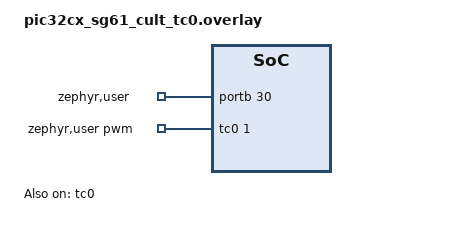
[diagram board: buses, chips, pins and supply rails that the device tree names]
/*
 * Copyright (c) 2026 Microchip Technology Inc.
 *
 * SPDX-License-Identifier: Apache-2.0
 */

/* connect the PB31 to PB30 */

#include <zephyr/dt-bindings/gpio/gpio.h>

/ {
	zephyr,user {
		pwms = <&tc0 1 PWM_MSEC(20) 0>;
		gpios = <&portb 30 GPIO_ACTIVE_HIGH>;
	};
};

&portb {
	status = "okay";
};

&tc0 {
	compatible = "microchip,tc-g1-pwm";
	#pwm-cells = <3>;
	pinctrl-0 = <&tc0_pwm_default>;
	pinctrl-names = "default";
	prescaler = <1>;
	max-bit-width = <32>;
	status = "okay";
};

&pinctrl {
	tc0_pwm_default: tc0_pwm_default {
		group1 {
			pinmux = <PB31E_TC0_WO1>;
		};
	};
};
